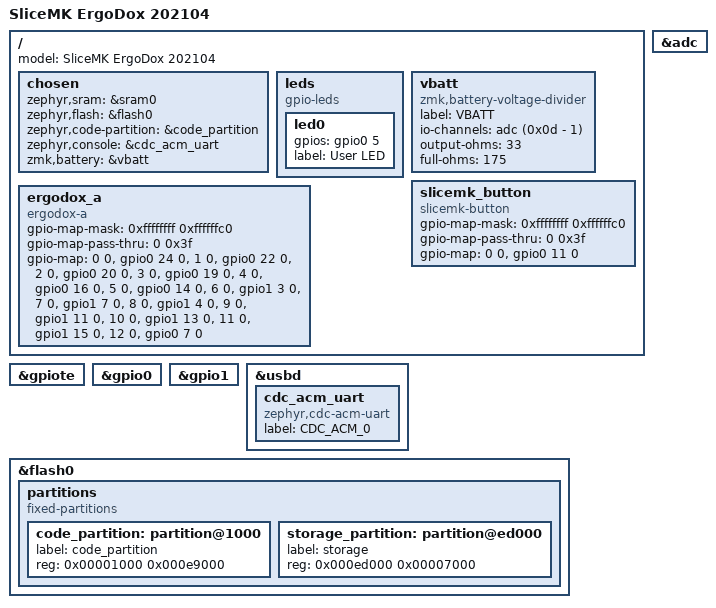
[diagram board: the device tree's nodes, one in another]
/dts-v1/;
#include <nordic/nrf52840_qiaa.dtsi>

/ {
    model = "SliceMK ErgoDox 202104";

    chosen {
        zephyr,sram = &sram0;
        zephyr,flash = &flash0;
        zephyr,code-partition = &code_partition;
        zephyr,console = &cdc_acm_uart;
        zmk,battery = &vbatt;
    };

    leds {
        compatible = "gpio-leds";
        led0: led0 {
            gpios = <&gpio0 5 GPIO_ACTIVE_HIGH>;
            label = "User LED";
        };
    };

    vbatt: vbatt {
        compatible = "zmk,battery-voltage-divider";
        label = "VBATT";
        io-channels = <&adc (0x0d - 1)>;
        output-ohms = <33>;
        full-ohms = <175>;
    };

    ergodox_a: ergodox_a {
        compatible = "ergodox-a";
        #gpio-cells = <2>;
        gpio-map-mask = <0xffffffff 0xffffffc0>;
        gpio-map-pass-thru = <0 0x3f>;
        gpio-map
            = <0 0 &gpio0 24 0>
            , <1 0 &gpio0 22 0>
            , <2 0 &gpio0 20 0>
            , <3 0 &gpio0 19 0>
            , <4 0 &gpio0 16 0>
            , <5 0 &gpio0 14 0>
            , <6 0 &gpio1 3 0>
            , <7 0 &gpio1 7 0>
            , <8 0 &gpio1 4 0>
            , <9 0 &gpio1 11 0>
            , <10 0 &gpio1 13 0>
            , <11 0 &gpio1 15 0>
            , <12 0 &gpio0 7 0>
            ;
    };

    slicemk_button: slicemk_button {
        compatible = "slicemk-button";
        #gpio-cells = <2>;
        gpio-map-mask = <0xffffffff 0xffffffc0>;
        gpio-map-pass-thru = <0 0x3f>;
        gpio-map = <0 0 &gpio0 11 0>;
    };
};

&adc {
    status = "okay";
};

&gpiote {
    status = "okay";
};

&gpio0 {
    status = "okay";
};

&gpio1 {
    status = "okay";
};

&usbd {
    status = "okay";
    cdc_acm_uart: cdc_acm_uart {
        compatible = "zephyr,cdc-acm-uart";
        label = "CDC_ACM_0";
    };
};

&flash0 {
    partitions {
        compatible = "fixed-partitions";
        #address-cells = <1>;
        #size-cells = <1>;

        code_partition: partition@1000 {
            label = "code_partition";
            reg = <0x00001000 0x000e9000>;
        };

        // Define storage partition before the bootloader, which starts at
        // 0xf4000. Only 7 pages is allocated for storage since that's the
        // default on the older Adafruit bootloader that these solar PCBs are
        // preloaded with.
        storage_partition: partition@ed000 {
            label = "storage";
            reg = <0x000ed000 0x00007000>;
        };
    };
};
